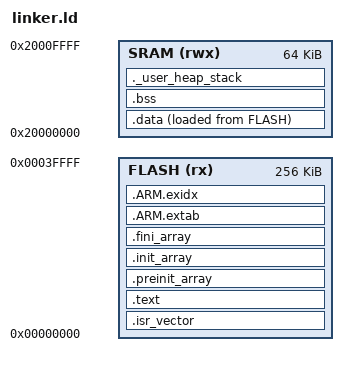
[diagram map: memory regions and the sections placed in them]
ENTRY(Reset_Handler)

_Min_Heap_Size  = 0x400;
_Min_Stack_Size = 0x800;

MEMORY
{
    FLASH (rx)  : ORIGIN = 0x00000000, LENGTH = 256K
    SRAM  (rwx) : ORIGIN = 0x20000000, LENGTH = 64K
}

_estack = ORIGIN(SRAM) + LENGTH(SRAM);

SECTIONS
{
    .isr_vector :
    {
        . = ALIGN(4);
        KEEP(*(.isr_vector))
    } > FLASH

    .text :
    {
        . = ALIGN(4);
        *(.text*)
        *(.rodata*)
        *(.glue_7) *(.glue_7t)
        KEEP(*(.init))
        KEEP(*(.fini))
        . = ALIGN(4);
        _etext = .;
    } > FLASH

    .preinit_array : { PROVIDE_HIDDEN(__preinit_array_start = .); KEEP(*(.preinit_array*)); PROVIDE_HIDDEN(__preinit_array_end = .); } > FLASH
    .init_array    : { PROVIDE_HIDDEN(__init_array_start = .);    KEEP(*(SORT(.init_array.*))); KEEP(*(.init_array*)); PROVIDE_HIDDEN(__init_array_end = .); } > FLASH
    .fini_array    : { PROVIDE_HIDDEN(__fini_array_start = .);    KEEP(*(SORT(.fini_array.*))); KEEP(*(.fini_array*)); PROVIDE_HIDDEN(__fini_array_end = .); } > FLASH

    .ARM.extab : { *(.ARM.extab* .gnu.linkonce.armextab.*) } > FLASH
    .ARM.exidx : { __exidx_start = .; *(.ARM.exidx*) __exidx_end = .; } > FLASH

    _sidata = LOADADDR(.data);

    .data :
    {
        . = ALIGN(4);
        _sdata = .;
        *(.data*)
        . = ALIGN(4);
        _edata = .;
    } > SRAM AT > FLASH

    .bss (NOLOAD) :
    {
        . = ALIGN(4);
        _sbss = .;
        *(.bss*)
        *(COMMON)
        . = ALIGN(4);
        _ebss = .;
    } > SRAM

    ._user_heap_stack (NOLOAD) :
    {
        . = ALIGN(8);
        _end = .;
        . = . + _Min_Heap_Size;
        . = . + _Min_Stack_Size;
        . = ALIGN(8);
    } > SRAM
}
